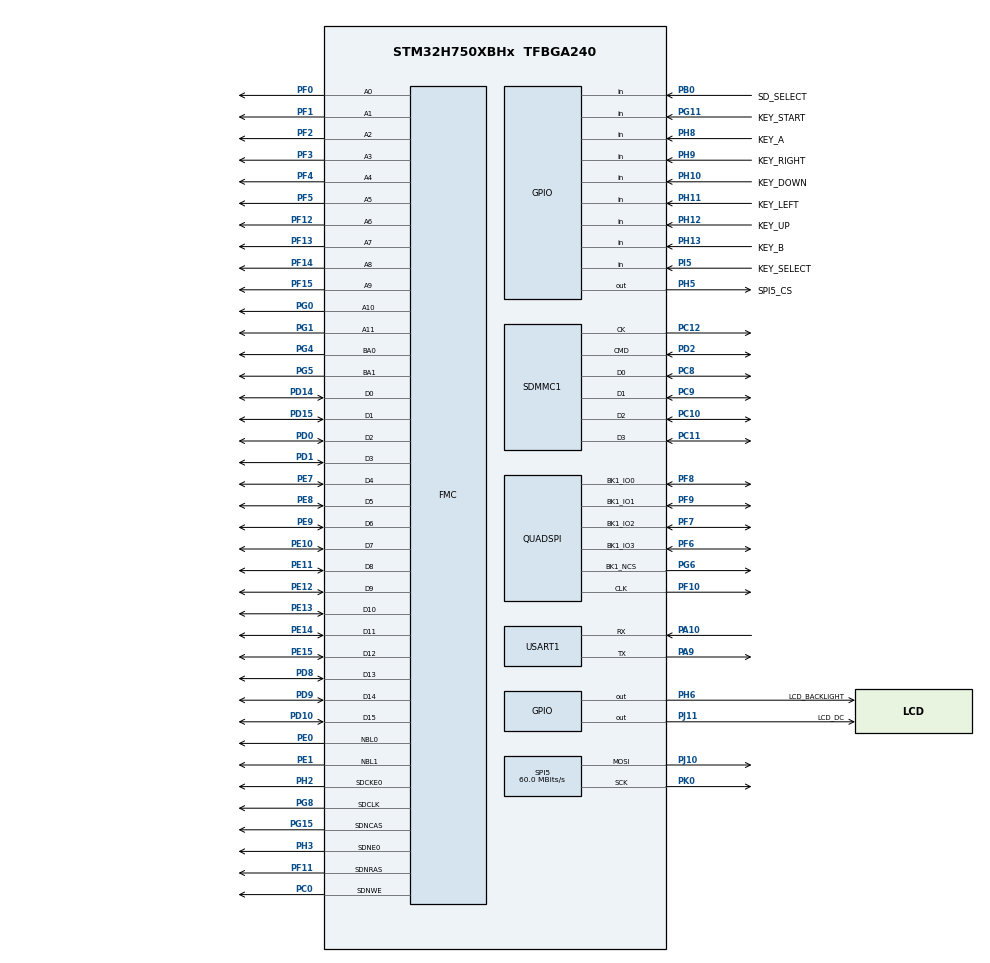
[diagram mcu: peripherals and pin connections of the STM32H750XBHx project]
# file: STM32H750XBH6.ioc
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CORTEX_M7.AccessPermission-Cortex_Memory_Protection_Unit_Region0_Settings=MPU_REGION_FULL_ACCESS
CORTEX_M7.AccessPermission-Cortex_Memory_Protection_Unit_Region1_Settings=MPU_REGION_FULL_ACCESS
CORTEX_M7.AccessPermission-Cortex_Memory_Protection_Unit_Region2_Settings=MPU_REGION_FULL_ACCESS
CORTEX_M7.BaseAddress-Cortex_Memory_Protection_Unit_Region0_Settings=0xC0000000
CORTEX_M7.BaseAddress-Cortex_Memory_Protection_Unit_Region1_Settings=0x38000000
CORTEX_M7.BaseAddress-Cortex_Memory_Protection_Unit_Region2_Settings=0x2407C000
CORTEX_M7.CPU_DCache=Enabled
CORTEX_M7.CPU_ICache=Enabled
CORTEX_M7.Enable-Cortex_Memory_Protection_Unit_Region0_Settings=MPU_REGION_ENABLE
CORTEX_M7.Enable-Cortex_Memory_Protection_Unit_Region1_Settings=MPU_REGION_ENABLE
CORTEX_M7.Enable-Cortex_Memory_Protection_Unit_Region2_Settings=MPU_REGION_ENABLE
CORTEX_M7.IsCacheable-Cortex_Memory_Protection_Unit_Region0_Settings=MPU_ACCESS_CACHEABLE
CORTEX_M7.MPU_Control=MPU_PRIVILEGED_DEFAULT
CORTEX_M7.Size-Cortex_Memory_Protection_Unit_Region0_Settings=MPU_REGION_SIZE_32MB
CORTEX_M7.Size-Cortex_Memory_Protection_Unit_Region1_Settings=MPU_REGION_SIZE_64KB
CORTEX_M7.Size-Cortex_Memory_Protection_Unit_Region2_Settings=MPU_REGION_SIZE_16KB
Dma.Request0=SPI5_TX
Dma.SPI5_TX.0.Direction=DMA_MEMORY_TO_PERIPH
Dma.SPI5_TX.0.EventEnable=DISABLE
Dma.SPI5_TX.0.FIFOMode=DMA_FIFOMODE_ENABLE
Dma.SPI5_TX.0.FIFOThreshold=DMA_FIFO_THRESHOLD_FULL
Dma.SPI5_TX.0.Instance=DMA1_Stream0
Dma.SPI5_TX.0.MemBurst=DMA_MBURST_SINGLE
Dma.SPI5_TX.0.MemDataAlignment=DMA_MDATAALIGN_BYTE
Dma.SPI5_TX.0.MemInc=DMA_MINC_ENABLE
Dma.SPI5_TX.0.Mode=DMA_NORMAL
Dma.SPI5_TX.0.PeriphBurst=DMA_PBURST_SINGLE
Dma.SPI5_TX.0.PeriphDataAlignment=DMA_PDATAALIGN_BYTE
Dma.SPI5_TX.0.PeriphInc=DMA_PINC_DISABLE
Dma.SPI5_TX.0.Polarity=HAL_DMAMUX_REQ_GEN_RISING
Dma.SPI5_TX.0.Priority=DMA_PRIORITY_LOW
Dma.SPI5_TX.0.RequestNumber=1
Dma.SPI5_TX.0.SignalID=NONE
Dma.SPI5_TX.0.SyncEnable=DISABLE
Dma.SPI5_TX.0.SyncPolarity=HAL_DMAMUX_SYNC_NO_EVENT
Dma.SPI5_TX.0.SyncRequestNumber=1
Dma.SPI5_TX.0.SyncSignalID=NONE
FATFS.BSP.number=1
FATFS._USE_LFN=2
FATFS._USE_STRFUNC=0
FATFS0.BSP.STBoard=false
FATFS0.BSP.api=Unknown
FATFS0.BSP.instance=PB0
FATFS0.BSP.ip=GPIO
FATFS0.BSP.mode=Input
FATFS0.BSP.name=Detect_SDIO
FATFS0.BSP.solution=PB0
FMC.CASLatency1=FMC_SDRAM_CAS_LATENCY_3
FMC.ColumnBitsNumber1=FMC_SDRAM_COLUMN_BITS_NUM_9
FMC.ExitSelfRefreshDelay1=7
FMC.LoadToActiveDelay1=2
FMC.RCDDelay1=2
FMC.RPDelay1=2
FMC.ReadBurst1=FMC_SDRAM_RBURST_ENABLE
FMC.ReadPipeDelay1=FMC_SDRAM_RPIPE_DELAY_0
FMC.RowCycleDelay1=7
FMC.SDClockPeriod1=FMC_SDRAM_CLOCK_PERIOD_2
FMC.SelfRefreshTime1=4
FMC.WriteRecoveryTime1=3
FREERTOS.Tasks01=defaultTask,8,128,StartDefaultTask,Default,NULL,Dynamic,NULL,NULL;displayTask,32,512,StartDisplayTask,Default,NULL,Dynamic,NULL,NULL;emuTask,24,512,StartEmuTask,Default,NULL,Dynamic,NULL,NULL
FREERTOS.configTIMER_TASK_PRIORITY=48
Mcu.Family=STM32H7
Mcu.Name=STM32H750XBHx
Mcu.Package=TFBGA240
Mdma.MDMA_Channel0.Request0=SDMMC1_END_DATA
Mdma.MDMA_Channel0.RequestsNb=1
Mdma.MDMA_Channel0.SDMMC1_END_DATA.0.BlockCount=0
Mdma.MDMA_Channel0.SDMMC1_END_DATA.0.BlockDataLength=0
Mdma.MDMA_Channel0.SDMMC1_END_DATA.0.BufferTransferLength=1
Mdma.MDMA_Channel0.SDMMC1_END_DATA.0.CircularMode=MDMA_LINEAR_LIST
Mdma.MDMA_Channel0.SDMMC1_END_DATA.0.DataAlignment=MDMA_DATAALIGN_PACKENABLE
Mdma.MDMA_Channel0.SDMMC1_END_DATA.0.DestBlockAddressOffset=0
Mdma.MDMA_Channel0.SDMMC1_END_DATA.0.DestBurst=MDMA_DEST_BURST_SINGLE
Mdma.MDMA_Channel0.SDMMC1_END_DATA.0.DestDataSize=MDMA_DEST_DATASIZE_BYTE
Mdma.MDMA_Channel0.SDMMC1_END_DATA.0.DestinationInc=MDMA_DEST_INC_BYTE
Mdma.MDMA_Channel0.SDMMC1_END_DATA.0.DstAddress=0
Mdma.MDMA_Channel0.SDMMC1_END_DATA.0.Endianness=MDMA_LITTLE_ENDIANNESS_PRESERVE
Mdma.MDMA_Channel0.SDMMC1_END_DATA.0.Instance=MDMA_Channel0
Mdma.MDMA_Channel0.SDMMC1_END_DATA.0.MaskAddress=0
Mdma.MDMA_Channel0.SDMMC1_END_DATA.0.MaskData=0
Mdma.MDMA_Channel0.SDMMC1_END_DATA.0.Priority=MDMA_PRIORITY_LOW
Mdma.MDMA_Channel0.SDMMC1_END_DATA.0.Rank=First
Mdma.MDMA_Channel0.SDMMC1_END_DATA.0.SourceBlockAddressOffset=0
Mdma.MDMA_Channel0.SDMMC1_END_DATA.0.SourceBurst=MDMA_SOURCE_BURST_SINGLE
Mdma.MDMA_Channel0.SDMMC1_END_DATA.0.SourceDataSize=MDMA_SRC_DATASIZE_BYTE
Mdma.MDMA_Channel0.SDMMC1_END_DATA.0.SourceInc=MDMA_SRC_INC_BYTE
Mdma.MDMA_Channel0.SDMMC1_END_DATA.0.SrcAddress=0
Mdma.MDMA_Channel0.SDMMC1_END_DATA.0.TransferTriggerMode=MDMA_BUFFER_TRANSFER
Mdma.RequestSet0=MDMA_Channel0
Mdma.RequestSetsNb=1
NVIC.DMA1_Stream0_IRQn=true\:5\:0\:false\:false\:true\:true\:false\:true\:true
NVIC.MDMA_IRQn=true\:5\:0\:false\:false\:true\:true\:false\:true\:true
NVIC.PriorityGroup=NVIC_PRIORITYGROUP_4
NVIC.SDMMC1_IRQn=true\:5\:0\:false\:false\:true\:true\:true\:true\:true
NVIC.SPI5_IRQn=true\:5\:0\:false\:false\:true\:true\:false\:true\:true
NVIC.TIM2_IRQn=true\:15\:0\:false\:false\:true\:false\:false\:true\:true
NVIC.TimeBase=TIM2_IRQn
NVIC.TimeBaseIP=TIM2
PA10.Mode=Asynchronous
PA10.Signal=USART1_RX
PA9.Mode=Asynchronous
PA9.Signal=USART1_TX
PB0.GPIO_Label=SD_SELECT
PB0.GPIO_PuPd=GPIO_PULLDOWN
PB0.Signal=GPIO_Input
PC0.Signal=FMC_SDNWE
PC10.Mode=SD_4_bits_Wide_bus
PC10.Signal=SDMMC1_D2
PC11.Mode=SD_4_bits_Wide_bus
PC11.Signal=SDMMC1_D3
PC12.Mode=SD_4_bits_Wide_bus
PC12.Signal=SDMMC1_CK
PC8.Mode=SD_4_bits_Wide_bus
PC8.Signal=SDMMC1_D0
PC9.Mode=SD_4_bits_Wide_bus
PC9.Signal=SDMMC1_D1
PD0.Signal=FMC_D2_DA2
PD1.Signal=FMC_D3_DA3
PD10.Signal=FMC_D15_DA15
PD14.Signal=FMC_D0_DA0
PD15.Signal=FMC_D1_DA1
PD2.Mode=SD_4_bits_Wide_bus
PD2.Signal=SDMMC1_CMD
PD8.Signal=FMC_D13_DA13
PD9.Signal=FMC_D14_DA14
PE0.Signal=FMC_NBL0
PE1.Signal=FMC_NBL1
PE10.Signal=FMC_D7_DA7
PE11.Signal=FMC_D8_DA8
PE12.Signal=FMC_D9_DA9
PE13.Signal=FMC_D10_DA10
PE14.Signal=FMC_D11_DA11
PE15.Signal=FMC_D12_DA12
PE7.Signal=FMC_D4_DA4
PE8.Signal=FMC_D5_DA5
PE9.Signal=FMC_D6_DA6
PF0.Signal=FMC_A0
PF1.Signal=FMC_A1
PF10.GPIO_Speed=GPIO_SPEED_FREQ_VERY_HIGH
PF10.Mode=Single Bank 1
PF10.Signal=QUADSPI_CLK
PF11.Signal=FMC_SDNRAS
PF12.Signal=FMC_A6
PF13.Signal=FMC_A7
PF14.Signal=FMC_A8
PF15.Signal=FMC_A9
PF2.Signal=FMC_A2
PF3.Signal=FMC_A3
PF4.Signal=FMC_A4
PF5.Signal=FMC_A5
PF6.GPIO_Speed=GPIO_SPEED_FREQ_VERY_HIGH
PF6.Mode=Single Bank 1
PF6.Signal=QUADSPI_BK1_IO3
PF7.GPIO_Speed=GPIO_SPEED_FREQ_VERY_HIGH
PF7.Mode=Single Bank 1
PF7.Signal=QUADSPI_BK1_IO2
PF8.GPIO_Speed=GPIO_SPEED_FREQ_VERY_HIGH
PF8.Mode=Single Bank 1
PF8.Signal=QUADSPI_BK1_IO0
PF9.GPIO_Speed=GPIO_SPEED_FREQ_VERY_HIGH
PF9.Mode=Single Bank 1
PF9.Signal=QUADSPI_BK1_IO1
PG0.Signal=FMC_A10
PG1.Signal=FMC_A11
PG11.GPIO_Label=KEY_START
PG11.GPIO_PuPd=GPIO_PULLUP
PG11.Signal=GPIO_Input
PG15.Signal=FMC_SDNCAS
PG4.Signal=FMC_A14_BA0
PG5.Signal=FMC_A15_BA1
PG6.GPIO_Speed=GPIO_SPEED_FREQ_VERY_HIGH
PG6.Mode=Single Bank 1
PG6.Signal=QUADSPI_BK1_NCS
PG8.Signal=FMC_SDCLK
PH0-OSC_IN\ (PH0).Mode=HSE-External-Oscillator
PH0-OSC_IN\ (PH0).Signal=RCC_OSC_IN
PH1-OSC_OUT\ (PH1).Mode=HSE-External-Oscillator
PH1-OSC_OUT\ (PH1).Signal=RCC_OSC_OUT
PH10.GPIO_Label=KEY_DOWN
PH10.GPIO_PuPd=GPIO_PULLUP
PH10.Signal=GPIO_Input
PH11.GPIO_Label=KEY_LEFT
PH11.GPIO_PuPd=GPIO_PULLUP
PH11.Signal=GPIO_Input
PH12.GPIO_Label=KEY_UP
PH12.GPIO_PuPd=GPIO_PULLUP
PH12.Signal=GPIO_Input
PH13.GPIO_Label=KEY_B
PH13.GPIO_PuPd=GPIO_PULLUP
PH13.Signal=GPIO_Input
PH2.Mode=SdramChipSelect1_1
PH2.Signal=FMC_SDCKE0
PH3.Mode=SdramChipSelect1_1
PH3.Signal=FMC_SDNE0
PH5.GPIO_Label=SPI5_CS
PH5.GPIO_Speed=GPIO_SPEED_FREQ_VERY_HIGH
PH5.Signal=GPIO_Output
PH6.GPIO_Label=LCD_BACKLIGHT
PH6.PinState=GPIO_PIN_SET
PH6.Signal=GPIO_Output
PH8.GPIO_Label=KEY_A
PH8.GPIO_PuPd=GPIO_PULLUP
PH8.Signal=GPIO_Input
PH9.GPIO_Label=KEY_RIGHT
PH9.GPIO_PuPd=GPIO_PULLUP
PH9.Signal=GPIO_Input
PI5.GPIO_Label=KEY_SELECT
PI5.GPIO_PuPd=GPIO_PULLUP
PI5.Signal=GPIO_Input
PJ10.GPIO_Speed=GPIO_SPEED_FREQ_VERY_HIGH
PJ10.Mode=TX_Only_Simplex_Unidirect_Master
PJ10.Signal=SPI5_MOSI
PJ11.GPIO_Label=LCD_DC
PJ11.PinState=GPIO_PIN_RESET
PJ11.Signal=GPIO_Output
PK0.GPIO_Speed=GPIO_SPEED_FREQ_VERY_HIGH
PK0.Mode=TX_Only_Simplex_Unidirect_Master
PK0.Signal=SPI5_SCK
ProjectManager.HeapSize=0x3000
ProjectManager.StackSize=0x2000
ProjectManager.TargetToolchain=MDK-ARM V5.32
QUADSPI.ClockMode=QSPI_CLOCK_MODE_0
QUADSPI.ClockPrescaler=1
QUADSPI.FifoThreshold=32
QUADSPI.FlashSize=23
QUADSPI.SampleShifting=QSPI_SAMPLE_SHIFTING_HALFCYCLE
RCC.ADCFreq_Value=50390625
RCC.APB1Freq_Value=120000000
RCC.APB2Freq_Value=120000000
RCC.APB3Freq_Value=120000000
RCC.APB4Freq_Value=120000000
RCC.CortexFreq_Value=480000000
RCC.D1PPRE=RCC_APB3_DIV2
RCC.D2PPRE1=RCC_APB1_DIV2
RCC.D2PPRE2=RCC_APB2_DIV2
RCC.D3PPRE=RCC_APB4_DIV2
RCC.DIVM1=5
RCC.DIVM3=5
RCC.DIVN1=192
RCC.DIVN3=100
RCC.DIVQ1=4
RCC.DIVQ3=50
RCC.DIVR3=50
RCC.HCLKFreq_Value=240000000
RCC.HPRE=RCC_HCLK_DIV2
RCC.PLLSourceVirtual=RCC_PLLSOURCE_HSE
RCC.ProductRev=revV
RCC.RTCClockSelection=RCC_RTCCLKSOURCE_LSE
RCC.SYSCLKFreq_VALUE=480000000
RCC.SYSCLKSource=RCC_SYSCLKSOURCE_PLLCLK
RCC.USBFreq_Value=240000000
SDMMC1.ClockDiv=2
SH.FMC_A0.0=FMC_A0,12b-sda1
SH.FMC_A1.0=FMC_A1,12b-sda1
SH.FMC_A10.0=FMC_A10,12b-sda1
SH.FMC_A11.0=FMC_A11,12b-sda1
SH.FMC_A14_BA0.0=FMC_BA0,FourSdramBanks1
SH.FMC_A15_BA1.0=FMC_BA1,FourSdramBanks1
SH.FMC_A2.0=FMC_A2,12b-sda1
SH.FMC_A3.0=FMC_A3,12b-sda1
SH.FMC_A4.0=FMC_A4,12b-sda1
SH.FMC_A5.0=FMC_A5,12b-sda1
SH.FMC_A6.0=FMC_A6,12b-sda1
SH.FMC_A7.0=FMC_A7,12b-sda1
SH.FMC_A8.0=FMC_A8,12b-sda1
SH.FMC_A9.0=FMC_A9,12b-sda1
SH.FMC_D0_DA0.0=FMC_D0,sd-16b-d1
SH.FMC_D10_DA10.0=FMC_D10,sd-16b-d1
SH.FMC_D11_DA11.0=FMC_D11,sd-16b-d1
SH.FMC_D12_DA12.0=FMC_D12,sd-16b-d1
SH.FMC_D13_DA13.0=FMC_D13,sd-16b-d1
SH.FMC_D14_DA14.0=FMC_D14,sd-16b-d1
SH.FMC_D15_DA15.0=FMC_D15,sd-16b-d1
SH.FMC_D1_DA1.0=FMC_D1,sd-16b-d1
SH.FMC_D2_DA2.0=FMC_D2,sd-16b-d1
SH.FMC_D3_DA3.0=FMC_D3,sd-16b-d1
SH.FMC_D4_DA4.0=FMC_D4,sd-16b-d1
SH.FMC_D5_DA5.0=FMC_D5,sd-16b-d1
SH.FMC_D6_DA6.0=FMC_D6,sd-16b-d1
SH.FMC_D7_DA7.0=FMC_D7,sd-16b-d1
SH.FMC_D8_DA8.0=FMC_D8,sd-16b-d1
SH.FMC_D9_DA9.0=FMC_D9,sd-16b-d1
SH.FMC_NBL0.0=FMC_NBL0,Sd2ByteEnable1
SH.FMC_NBL1.0=FMC_NBL1,Sd2ByteEnable1
SH.FMC_SDCLK.0=FMC_SDCLK,12b-sda1
SH.FMC_SDNCAS.0=FMC_SDNCAS,12b-sda1
SH.FMC_SDNRAS.0=FMC_SDNRAS,12b-sda1
SH.FMC_SDNWE.0=FMC_SDNWE,12b-sda1
SPI5.CalculateBaudRate=60.0 MBits/s
SPI5.DataSize=SPI_DATASIZE_8BIT
SPI5.Direction=SPI_DIRECTION_2LINES_TXONLY
SPI5.FifoThreshold=SPI_FIFO_THRESHOLD_02DATA
SPI5.Mode=SPI_MODE_MASTER
SPI5.VirtualType=VM_MASTER
STMicroelectronics.X-CUBE-TOUCHGFX.4.20.0.tgfx_address1=0xC0000000
STMicroelectronics.X-CUBE-TOUCHGFX.4.20.0.tgfx_address2=0xC00BB800
STMicroelectronics.X-CUBE-TOUCHGFX.4.20.0.tgfx_buffering_strategy=Double
STMicroelectronics.X-CUBE-TOUCHGFX.4.20.0.tgfx_custom_height=480
STMicroelectronics.X-CUBE-TOUCHGFX.4.20.0.tgfx_display_interface=disp_ltdc
STMicroelectronics.X-CUBE-TOUCHGFX.4.20.0.tgfx_hardware_accelerator=dma_2d
STMicroelectronics.X-CUBE-TOUCHGFX.4.20.0.tgfx_location=By Address
STMicroelectronics.X-CUBE-TOUCHGFX.4.20.0.tgfx_vsync=vsync_ltdc
STMicroelectronics.X-CUBE-TOUCHGFX.4.20.0_IsPackSelfContextualization=true
USART1.VirtualMode-Asynchronous=VM_ASYNC
VP_FATFS_VS_SDIO.Mode=SDIO
VP_FREERTOS_VS_CMSIS_V2.Mode=CMSIS_V2
VP_SYS_VS_tim2.Mode=TIM2
board=custom

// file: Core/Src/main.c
/* USER CODE BEGIN Header */
/**
  ******************************************************************************
  * @file           : main.c
  * @brief          : Main program body
  ******************************************************************************
  * @attention
  *
  * Copyright (c) 2023 STMicroelectronics.
  * All rights reserved.
  *
  * This software is licensed under terms that can be found in the LICENSE file
  * in the root directory of this software component.
  * If no LICENSE file comes with this software, it is provided AS-IS.
  *
  ******************************************************************************
  */
/* USER CODE END Header */
#include "main.h"
#include "cmsis_os.h"
#include "fatfs.h"

/* USER CODE BEGIN Includes */
#include <string.h>
#include "spi_drv.h"
#include "stm32h7_emu.h"
/* USER CODE END Includes */

QSPI_HandleTypeDef hqspi;

SD_HandleTypeDef hsd1;

SPI_HandleTypeDef hspi5;
DMA_HandleTypeDef hdma_spi5_tx;

UART_HandleTypeDef huart1;

MDMA_HandleTypeDef hmdma_mdma_channel0_sdmmc1_end_data_0;
SDRAM_HandleTypeDef hsdram1;

/* Definitions for defaultTask */
osThreadId_t defaultTaskHandle;
const osThreadAttr_t defaultTask_attributes = {
  .name = "defaultTask",
  .stack_size = 128 * 4,
  .priority = (osPriority_t) osPriorityLow,
};
/* Definitions for displayTask */
osThreadId_t displayTaskHandle;
const osThreadAttr_t displayTask_attributes = {
  .name = "displayTask",
  .stack_size = 512 * 4,
  .priority = (osPriority_t) osPriorityAboveNormal,
};
/* Definitions for emuTask */
osThreadId_t emuTaskHandle;
const osThreadAttr_t emuTask_attributes = {
  .name = "emuTask",
  .stack_size = 512 * 4,
  .priority = (osPriority_t) osPriorityNormal,
};

void SystemClock_Config(void);
static void MPU_Initialize(void);
static void MPU_Config(void);
static void MX_GPIO_Init(void);
static void MX_DMA_Init(void);
static void MX_MDMA_Init(void);
static void MX_QUADSPI_Init(void);
static void MX_SDMMC1_SD_Init(void);
static void MX_USART1_UART_Init(void);
static void MX_FMC_Init(void);
static void MX_SPI5_Init(void);
void StartDefaultTask(void *argument);
void StartDisplayTask(void *argument);
void StartEmuTask(void *argument);

/* USER CODE BEGIN 0 */
#define SDRAM_BANK_ADDR     ((uint32_t)0xC0000000) 				// FMC SDRAM 数据基地址
#define FMC_COMMAND_TARGET_BANK   FMC_SDRAM_CMD_TARGET_BANK1	//	SDRAM 的bank选择
#define SDRAM_TIMEOUT     ((uint32_t)0x1000) 						// 超时判断时间

#define SDRAM_MODEREG_BURST_LENGTH_1             ((uint16_t)0x0000)
#define SDRAM_MODEREG_BURST_LENGTH_2             ((uint16_t)0x0001)
#define SDRAM_MODEREG_BURST_LENGTH_4             ((uint16_t)0x0002)
#define SDRAM_MODEREG_BURST_LENGTH_8             ((uint16_t)0x0004)
#define SDRAM_MODEREG_BURST_TYPE_SEQUENTIAL      ((uint16_t)0x0000)
#define SDRAM_MODEREG_BURST_TYPE_INTERLEAVED     ((uint16_t)0x0008)
#define SDRAM_MODEREG_CAS_LATENCY_2              ((uint16_t)0x0020)
#define SDRAM_MODEREG_CAS_LATENCY_3              ((uint16_t)0x0030)
#define SDRAM_MODEREG_OPERATING_MODE_STANDARD    ((uint16_t)0x0000)
#define SDRAM_MODEREG_WRITEBURST_MODE_PROGRAMMED ((uint16_t)0x0000)
#define SDRAM_MODEREG_WRITEBURST_MODE_SINGLE     ((uint16_t)0x0200)

void SDRAM_Initialization_Sequence(SDRAM_HandleTypeDef *hsdram, FMC_SDRAM_CommandTypeDef *Command)
{
    __IO uint32_t tmpmrd = 0;

    /* Configure a clock configuration enable command */
    Command->CommandMode                = FMC_SDRAM_CMD_CLK_ENABLE;	// 开启SDRAM时钟
    Command->CommandTarget              = FMC_COMMAND_TARGET_BANK; 	// 选择要控制的区域
    Command->AutoRefreshNumber          = 1;
    Command->ModeRegisterDefinition     = 0;

    HAL_SDRAM_SendCommand(hsdram, Command, SDRAM_TIMEOUT);  // 发送控制指令
    HAL_Delay(1);		// 延时等待

    /* Configure a PALL (precharge all) command */
    Command->CommandMode                = FMC_SDRAM_CMD_PALL;       // 预充电命令
    Command->CommandTarget              = FMC_COMMAND_TARGET_BANK;  // 选择要控制的区域
    Command->AutoRefreshNumber          = 1;
    Command->ModeRegisterDefinition     = 0;

    HAL_SDRAM_SendCommand(hsdram, Command, SDRAM_TIMEOUT);  // 发送控制指令

    /* Configure a Auto-Refresh command */
    Command->CommandMode                = FMC_SDRAM_CMD_AUTOREFRESH_MODE;   // 使用自动刷新
    Command->CommandTarget              = FMC_COMMAND_TARGET_BANK;          // 选择要控制的区域
    Command->AutoRefreshNumber          = 8;                                // 自动刷新次数
    Command->ModeRegisterDefinition     = 0;

    HAL_SDRAM_SendCommand(hsdram, Command, SDRAM_TIMEOUT);  // 发送控制指令

    /* Program the external memory mode register */
    tmpmrd = (uint32_t)SDRAM_MODEREG_BURST_LENGTH_1 |
                            SDRAM_MODEREG_BURST_TYPE_SEQUENTIAL |
                            SDRAM_MODEREG_CAS_LATENCY_3 |
                            SDRAM_MODEREG_OPERATING_MODE_STANDARD   |
                            SDRAM_MODEREG_WRITEBURST_MODE_SINGLE;

    Command->CommandMode                = FMC_SDRAM_CMD_LOAD_MODE;  // 加载模式寄存器命令
    Command->CommandTarget              = FMC_COMMAND_TARGET_BANK;  // 选择要控制的区域
    Command->AutoRefreshNumber          = 1;
    Command->ModeRegisterDefinition     = tmpmrd;

    HAL_SDRAM_SendCommand(hsdram, Command, SDRAM_TIMEOUT);  // 发送控制指令

    HAL_SDRAM_ProgramRefreshRate(hsdram, 1543);  // 配置刷新率
}

/* USER CODE END 0 */

int main(void)
{

  /* Enable I-Cache---------------------------------------------------------*/
  SCB_EnableICache();

  /* Enable D-Cache---------------------------------------------------------*/
  SCB_EnableDCache();

  /* MCU Configuration--------------------------------------------------------*/

  /* Reset of all peripherals, Initializes the Flash interface and the Systick. */
  HAL_Init();

  /* MPU Configuration--------------------------------------------------------*/
  MPU_Config();

  /* Configure the system clock */
  SystemClock_Config();

  /* Initialize all configured peripherals */
  MX_GPIO_Init();
  MX_DMA_Init();
  MX_MDMA_Init();
  MX_QUADSPI_Init();
  MX_SDMMC1_SD_Init();
  MX_USART1_UART_Init();
  MX_FMC_Init();
  MX_SPI5_Init();
  MX_FATFS_Init();
  /* USER CODE BEGIN 2 */
  spi_init();
  /* USER CODE END 2 */

  /* Init scheduler */
  osKernelInitialize();

  /* Create the thread(s) */
  /* creation of defaultTask */
  defaultTaskHandle = osThreadNew(StartDefaultTask, NULL, &defaultTask_attributes);

  /* creation of displayTask */
  displayTaskHandle = osThreadNew(StartDisplayTask, NULL, &displayTask_attributes);

  /* creation of emuTask */
  emuTaskHandle = osThreadNew(StartEmuTask, NULL, &emuTask_attributes);

  /* Start scheduler */
  osKernelStart();

  /* We should never get here as control is now taken by the scheduler */
  /* Infinite loop */
  while (1)
  {

  }
}

void SystemClock_Config(void)
{
  RCC_OscInitTypeDef RCC_OscInitStruct = {0};
  RCC_ClkInitTypeDef RCC_ClkInitStruct = {0};

  /** Supply configuration update enable
  */
  HAL_PWREx_ConfigSupply(PWR_LDO_SUPPLY);

  /** Configure the main internal regulator output voltage
  */
  __HAL_PWR_VOLTAGESCALING_CONFIG(PWR_REGULATOR_VOLTAGE_SCALE1);

  while(!__HAL_PWR_GET_FLAG(PWR_FLAG_VOSRDY)) {}

  __HAL_RCC_SYSCFG_CLK_ENABLE();
  __HAL_PWR_VOLTAGESCALING_CONFIG(PWR_REGULATOR_VOLTAGE_SCALE0);

  while(!__HAL_PWR_GET_FLAG(PWR_FLAG_VOSRDY)) {}

  /** Initializes the RCC Oscillators according to the specified parameters
  * in the RCC_OscInitTypeDef structure.
  */
  RCC_OscInitStruct.OscillatorType = RCC_OSCILLATORTYPE_HSE;
  RCC_OscInitStruct.HSEState = RCC_HSE_ON;
  RCC_OscInitStruct.PLL.PLLState = RCC_PLL_ON;
  RCC_OscInitStruct.PLL.PLLSource = RCC_PLLSOURCE_HSE;
  RCC_OscInitStruct.PLL.PLLM = 5;
  RCC_OscInitStruct.PLL.PLLN = 192;
  RCC_OscInitStruct.PLL.PLLP = 2;
  RCC_OscInitStruct.PLL.PLLQ = 4;
  RCC_OscInitStruct.PLL.PLLR = 2;
  RCC_OscInitStruct.PLL.PLLRGE = RCC_PLL1VCIRANGE_2;
  RCC_OscInitStruct.PLL.PLLVCOSEL = RCC_PLL1VCOWIDE;
  RCC_OscInitStruct.PLL.PLLFRACN = 0;
  if (HAL_RCC_OscConfig(&RCC_OscInitStruct) != HAL_OK)
  {
    Error_Handler();
  }

  /** Initializes the CPU, AHB and APB buses clocks
  */
  RCC_ClkInitStruct.ClockType = RCC_CLOCKTYPE_HCLK|RCC_CLOCKTYPE_SYSCLK
                              |RCC_CLOCKTYPE_PCLK1|RCC_CLOCKTYPE_PCLK2
                              |RCC_CLOCKTYPE_D3PCLK1|RCC_CLOCKTYPE_D1PCLK1;
  RCC_ClkInitStruct.SYSCLKSource = RCC_SYSCLKSOURCE_PLLCLK;
  RCC_ClkInitStruct.SYSCLKDivider = RCC_SYSCLK_DIV1;
  RCC_ClkInitStruct.AHBCLKDivider = RCC_HCLK_DIV2;
  RCC_ClkInitStruct.APB3CLKDivider = RCC_APB3_DIV2;
  RCC_ClkInitStruct.APB1CLKDivider = RCC_APB1_DIV2;
  RCC_ClkInitStruct.APB2CLKDivider = RCC_APB2_DIV2;
  RCC_ClkInitStruct.APB4CLKDivider = RCC_APB4_DIV2;

  if (HAL_RCC_ClockConfig(&RCC_ClkInitStruct, FLASH_LATENCY_4) != HAL_OK)
  {
    Error_Handler();
  }
}

static void MX_QUADSPI_Init(void)
{

  /* QUADSPI parameter configuration*/
  hqspi.Instance = QUADSPI;
  hqspi.Init.ClockPrescaler = 1;
  hqspi.Init.FifoThreshold = 32;
  hqspi.Init.SampleShifting = QSPI_SAMPLE_SHIFTING_HALFCYCLE;
  hqspi.Init.FlashSize = 23;
  hqspi.Init.ChipSelectHighTime = QSPI_CS_HIGH_TIME_1_CYCLE;
  hqspi.Init.ClockMode = QSPI_CLOCK_MODE_0;
  hqspi.Init.FlashID = QSPI_FLASH_ID_1;
  hqspi.Init.DualFlash = QSPI_DUALFLASH_DISABLE;
  if (HAL_QSPI_Init(&hqspi) != HAL_OK)
  {
    Error_Handler();
  }

}

static void MX_SDMMC1_SD_Init(void)
{

  hsd1.Instance = SDMMC1;
  hsd1.Init.ClockEdge = SDMMC_CLOCK_EDGE_RISING;
  hsd1.Init.ClockPowerSave = SDMMC_CLOCK_POWER_SAVE_DISABLE;
  hsd1.Init.BusWide = SDMMC_BUS_WIDE_4B;
  hsd1.Init.HardwareFlowControl = SDMMC_HARDWARE_FLOW_CONTROL_DISABLE;
  hsd1.Init.ClockDiv = 2;

}

static void MX_SPI5_Init(void)
{

  /* SPI5 parameter configuration*/
  hspi5.Instance = SPI5;
  hspi5.Init.Mode = SPI_MODE_MASTER;
  hspi5.Init.Direction = SPI_DIRECTION_2LINES_TXONLY;
  hspi5.Init.DataSize = SPI_DATASIZE_8BIT;
  hspi5.Init.CLKPolarity = SPI_POLARITY_LOW;
  hspi5.Init.CLKPhase = SPI_PHASE_1EDGE;
  hspi5.Init.NSS = SPI_NSS_SOFT;
  hspi5.Init.BaudRatePrescaler = SPI_BAUDRATEPRESCALER_2;
  hspi5.Init.FirstBit = SPI_FIRSTBIT_MSB;
  hspi5.Init.TIMode = SPI_TIMODE_DISABLE;
  hspi5.Init.CRCCalculation = SPI_CRCCALCULATION_DISABLE;
  hspi5.Init.CRCPolynomial = 0x0;
  hspi5.Init.NSSPMode = SPI_NSS_PULSE_ENABLE;
  hspi5.Init.NSSPolarity = SPI_NSS_POLARITY_LOW;
  hspi5.Init.FifoThreshold = SPI_FIFO_THRESHOLD_02DATA;
  hspi5.Init.TxCRCInitializationPattern = SPI_CRC_INITIALIZATION_ALL_ZERO_PATTERN;
  hspi5.Init.RxCRCInitializationPattern = SPI_CRC_INITIALIZATION_ALL_ZERO_PATTERN;
  hspi5.Init.MasterSSIdleness = SPI_MASTER_SS_IDLENESS_00CYCLE;
  hspi5.Init.MasterInterDataIdleness = SPI_MASTER_INTERDATA_IDLENESS_00CYCLE;
  hspi5.Init.MasterReceiverAutoSusp = SPI_MASTER_RX_AUTOSUSP_DISABLE;
  hspi5.Init.MasterKeepIOState = SPI_MASTER_KEEP_IO_STATE_DISABLE;
  hspi5.Init.IOSwap = SPI_IO_SWAP_DISABLE;
  if (HAL_SPI_Init(&hspi5) != HAL_OK)
  {
    Error_Handler();
  }

}

static void MX_USART1_UART_Init(void)
{

  huart1.Instance = USART1;
  huart1.Init.BaudRate = 115200;
  huart1.Init.WordLength = UART_WORDLENGTH_8B;
  huart1.Init.StopBits = UART_STOPBITS_1;
  huart1.Init.Parity = UART_PARITY_NONE;
  huart1.Init.Mode = UART_MODE_TX_RX;
  huart1.Init.HwFlowCtl = UART_HWCONTROL_NONE;
  huart1.Init.OverSampling = UART_OVERSAMPLING_16;
  huart1.Init.OneBitSampling = UART_ONE_BIT_SAMPLE_DISABLE;
  huart1.Init.ClockPrescaler = UART_PRESCALER_DIV1;
  huart1.AdvancedInit.AdvFeatureInit = UART_ADVFEATURE_NO_INIT;
  if (HAL_UART_Init(&huart1) != HAL_OK)
  {
    Error_Handler();
  }
  if (HAL_UARTEx_SetTxFifoThreshold(&huart1, UART_TXFIFO_THRESHOLD_1_8) != HAL_OK)
  {
    Error_Handler();
  }
  if (HAL_UARTEx_SetRxFifoThreshold(&huart1, UART_RXFIFO_THRESHOLD_1_8) != HAL_OK)
  {
    Error_Handler();
  }
  if (HAL_UARTEx_DisableFifoMode(&huart1) != HAL_OK)
  {
    Error_Handler();
  }

}

static void MX_DMA_Init(void)
{

  /* DMA controller clock enable */
  __HAL_RCC_DMA1_CLK_ENABLE();

  /* DMA interrupt init */
  /* DMA1_Stream0_IRQn interrupt configuration */
  HAL_NVIC_SetPriority(DMA1_Stream0_IRQn, 5, 0);
  HAL_NVIC_EnableIRQ(DMA1_Stream0_IRQn);

}

/**
  * Enable MDMA controller clock
  * Configure MDMA for global transfers
  *   hmdma_mdma_channel0_sdmmc1_end_data_0
  */
static void MX_MDMA_Init(void)
{

  /* MDMA controller clock enable */
  __HAL_RCC_MDMA_CLK_ENABLE();
  /* Local variables */

  /* Configure MDMA channel MDMA_Channel0 */
  /* Configure MDMA request hmdma_mdma_channel0_sdmmc1_end_data_0 on MDMA_Channel0 */
  hmdma_mdma_channel0_sdmmc1_end_data_0.Instance = MDMA_Channel0;
  hmdma_mdma_channel0_sdmmc1_end_data_0.Init.Request = MDMA_REQUEST_SDMMC1_END_DATA;
  hmdma_mdma_channel0_sdmmc1_end_data_0.Init.TransferTriggerMode = MDMA_BUFFER_TRANSFER;
  hmdma_mdma_channel0_sdmmc1_end_data_0.Init.Priority = MDMA_PRIORITY_LOW;
  hmdma_mdma_channel0_sdmmc1_end_data_0.Init.Endianness = MDMA_LITTLE_ENDIANNESS_PRESERVE;
  hmdma_mdma_channel0_sdmmc1_end_data_0.Init.SourceInc = MDMA_SRC_INC_BYTE;
  hmdma_mdma_channel0_sdmmc1_end_data_0.Init.DestinationInc = MDMA_DEST_INC_BYTE;
  hmdma_mdma_channel0_sdmmc1_end_data_0.Init.SourceDataSize = MDMA_SRC_DATASIZE_BYTE;
  hmdma_mdma_channel0_sdmmc1_end_data_0.Init.DestDataSize = MDMA_DEST_DATASIZE_BYTE;
  hmdma_mdma_channel0_sdmmc1_end_data_0.Init.DataAlignment = MDMA_DATAALIGN_PACKENABLE;
  hmdma_mdma_channel0_sdmmc1_end_data_0.Init.BufferTransferLength = 1;
  hmdma_mdma_channel0_sdmmc1_end_data_0.Init.SourceBurst = MDMA_SOURCE_BURST_SINGLE;
  hmdma_mdma_channel0_sdmmc1_end_data_0.Init.DestBurst = MDMA_DEST_BURST_SINGLE;
  hmdma_mdma_channel0_sdmmc1_end_data_0.Init.SourceBlockAddressOffset = 0;
  hmdma_mdma_channel0_sdmmc1_end_data_0.Init.DestBlockAddressOffset = 0;
  if (HAL_MDMA_Init(&hmdma_mdma_channel0_sdmmc1_end_data_0) != HAL_OK)
  {
    Error_Handler();
  }

  /* Configure post request address and data masks */
  if (HAL_MDMA_ConfigPostRequestMask(&hmdma_mdma_channel0_sdmmc1_end_data_0, 0, 0) != HAL_OK)
  {
    Error_Handler();
  }

  /* MDMA interrupt initialization */
  /* MDMA_IRQn interrupt configuration */
  HAL_NVIC_SetPriority(MDMA_IRQn, 5, 0);
  HAL_NVIC_EnableIRQ(MDMA_IRQn);

}

/* FMC initialization function */
static void MX_FMC_Init(void)
{

  FMC_SDRAM_TimingTypeDef SdramTiming = {0};

  /** Perform the SDRAM1 memory initialization sequence
  */
  hsdram1.Instance = FMC_SDRAM_DEVICE;
  /* hsdram1.Init */
  hsdram1.Init.SDBank = FMC_SDRAM_BANK1;
  hsdram1.Init.ColumnBitsNumber = FMC_SDRAM_COLUMN_BITS_NUM_9;
  hsdram1.Init.RowBitsNumber = FMC_SDRAM_ROW_BITS_NUM_12;
  hsdram1.Init.MemoryDataWidth = FMC_SDRAM_MEM_BUS_WIDTH_16;
  hsdram1.Init.InternalBankNumber = FMC_SDRAM_INTERN_BANKS_NUM_4;
  hsdram1.Init.CASLatency = FMC_SDRAM_CAS_LATENCY_3;
  hsdram1.Init.WriteProtection = FMC_SDRAM_WRITE_PROTECTION_DISABLE;
  hsdram1.Init.SDClockPeriod = FMC_SDRAM_CLOCK_PERIOD_2;
  hsdram1.Init.ReadBurst = FMC_SDRAM_RBURST_ENABLE;
  hsdram1.Init.ReadPipeDelay = FMC_SDRAM_RPIPE_DELAY_0;
  /* SdramTiming */
  SdramTiming.LoadToActiveDelay = 2;
  SdramTiming.ExitSelfRefreshDelay = 7;
  SdramTiming.SelfRefreshTime = 4;
  SdramTiming.RowCycleDelay = 7;
  SdramTiming.WriteRecoveryTime = 3;
  SdramTiming.RPDelay = 2;
  SdramTiming.RCDDelay = 2;

  if (HAL_SDRAM_Init(&hsdram1, &SdramTiming) != HAL_OK)
  {
    Error_Handler( );
  }

  /* USER CODE BEGIN FMC_Init 2 */
  FMC_SDRAM_CommandTypeDef command; // 控制指令
  SDRAM_Initialization_Sequence(&hsdram1,&command); //配置SDRAM
  /* USER CODE END FMC_Init 2 */
}

static void MX_GPIO_Init(void)
{
  GPIO_InitTypeDef GPIO_InitStruct = {0};

  /* GPIO Ports Clock Enable */
  __HAL_RCC_GPIOI_CLK_ENABLE();
  __HAL_RCC_GPIOC_CLK_ENABLE();
  __HAL_RCC_GPIOE_CLK_ENABLE();
  __HAL_RCC_GPIOG_CLK_ENABLE();
  __HAL_RCC_GPIOD_CLK_ENABLE();
  __HAL_RCC_GPIOA_CLK_ENABLE();
  __HAL_RCC_GPIOH_CLK_ENABLE();
  __HAL_RCC_GPIOF_CLK_ENABLE();
  __HAL_RCC_GPIOK_CLK_ENABLE();
  __HAL_RCC_GPIOJ_CLK_ENABLE();
  __HAL_RCC_GPIOB_CLK_ENABLE();

  /*Configure GPIO pin Output Level */
  HAL_GPIO_WritePin(LCD_DC_GPIO_Port, LCD_DC_Pin, GPIO_PIN_RESET);

  /*Configure GPIO pin Output Level */
  HAL_GPIO_WritePin(SPI5_CS_GPIO_Port, SPI5_CS_Pin, GPIO_PIN_RESET);

  /*Configure GPIO pin Output Level */
  HAL_GPIO_WritePin(LCD_BACKLIGHT_GPIO_Port, LCD_BACKLIGHT_Pin, GPIO_PIN_SET);

  /*Configure GPIO pin : KEY_SELECT_Pin */
  GPIO_InitStruct.Pin = KEY_SELECT_Pin;
  GPIO_InitStruct.Mode = GPIO_MODE_INPUT;
  GPIO_InitStruct.Pull = GPIO_PULLUP;
  HAL_GPIO_Init(KEY_SELECT_GPIO_Port, &GPIO_InitStruct);

  /*Configure GPIO pin : KEY_START_Pin */
  GPIO_InitStruct.Pin = KEY_START_Pin;
  GPIO_InitStruct.Mode = GPIO_MODE_INPUT;
  GPIO_InitStruct.Pull = GPIO_PULLUP;
  HAL_GPIO_Init(KEY_START_GPIO_Port, &GPIO_InitStruct);

  /*Configure GPIO pins : KEY_B_Pin KEY_DOWN_Pin KEY_LEFT_Pin KEY_RIGHT_Pin
                           KEY_UP_Pin KEY_A_Pin */
  GPIO_InitStruct.Pin = KEY_B_Pin|KEY_DOWN_Pin|KEY_LEFT_Pin|KEY_RIGHT_Pin
                          |KEY_UP_Pin|KEY_A_Pin;
  GPIO_InitStruct.Mode = GPIO_MODE_INPUT;
  GPIO_InitStruct.Pull = GPIO_PULLUP;
  HAL_GPIO_Init(GPIOH, &GPIO_InitStruct);

  /*Configure GPIO pin : LCD_DC_Pin */
  GPIO_InitStruct.Pin = LCD_DC_Pin;
  GPIO_InitStruct.Mode = GPIO_MODE_OUTPUT_PP;
  GPIO_InitStruct.Pull = GPIO_NOPULL;
  GPIO_InitStruct.Speed = GPIO_SPEED_FREQ_LOW;
  HAL_GPIO_Init(LCD_DC_GPIO_Port, &GPIO_InitStruct);

  /*Configure GPIO pin : SPI5_CS_Pin */
  GPIO_InitStruct.Pin = SPI5_CS_Pin;
  GPIO_InitStruct.Mode = GPIO_MODE_OUTPUT_PP;
  GPIO_InitStruct.Pull = GPIO_NOPULL;
  GPIO_InitStruct.Speed = GPIO_SPEED_FREQ_VERY_HIGH;
  HAL_GPIO_Init(SPI5_CS_GPIO_Port, &GPIO_InitStruct);

  /*Configure GPIO pin : LCD_BACKLIGHT_Pin */
  GPIO_InitStruct.Pin = LCD_BACKLIGHT_Pin;
  GPIO_InitStruct.Mode = GPIO_MODE_OUTPUT_PP;
  GPIO_InitStruct.Pull = GPIO_NOPULL;
  GPIO_InitStruct.Speed = GPIO_SPEED_FREQ_LOW;
  HAL_GPIO_Init(LCD_BACKLIGHT_GPIO_Port, &GPIO_InitStruct);

  /*Configure GPIO pin : SD_SELECT_Pin */
  GPIO_InitStruct.Pin = SD_SELECT_Pin;
  GPIO_InitStruct.Mode = GPIO_MODE_INPUT;
  GPIO_InitStruct.Pull = GPIO_PULLDOWN;
  HAL_GPIO_Init(SD_SELECT_GPIO_Port, &GPIO_InitStruct);

}

void StartDefaultTask(void *argument)
{
  /* USER CODE BEGIN 5 */
  /* Infinite loop */
  for(;;)
  {
    osDelay(1000);
  }
  /* USER CODE END 5 */
}

void StartDisplayTask(void *argument)
{
  /* USER CODE BEGIN StartDisplayTask */
  stm32h7_draw_init();
  /* Infinite loop */
  for(;;)
  {
    stm32h7_draw_handle();
  }
  /* USER CODE END StartDisplayTask */
}

void StartEmuTask(void *argument)
{
  /* USER CODE BEGIN StartEmuTask */
  stm32h7_emu_init();
  /* Infinite loop */
  for(;;)
  {
    stm32h7_emu_handle();
  }
  /* USER CODE END StartEmuTask */
}

/* MPU Configuration */

void MPU_Config(void)
{
  MPU_Region_InitTypeDef MPU_InitStruct = {0};

  /* Disables the MPU */
  HAL_MPU_Disable();

  /** Initializes and configures the Region and the memory to be protected
  */
  MPU_InitStruct.Enable = MPU_REGION_ENABLE;
  MPU_InitStruct.Number = MPU_REGION_NUMBER0;
  MPU_InitStruct.BaseAddress = 0xC0000000;
  MPU_InitStruct.Size = MPU_REGION_SIZE_32MB;
  MPU_InitStruct.SubRegionDisable = 0x0;
  MPU_InitStruct.TypeExtField = MPU_TEX_LEVEL0;
  MPU_InitStruct.AccessPermission = MPU_REGION_FULL_ACCESS;
  MPU_InitStruct.DisableExec = MPU_INSTRUCTION_ACCESS_ENABLE;
  MPU_InitStruct.IsShareable = MPU_ACCESS_NOT_SHAREABLE;
  MPU_InitStruct.IsCacheable = MPU_ACCESS_CACHEABLE;
  MPU_InitStruct.IsBufferable = MPU_ACCESS_NOT_BUFFERABLE;

  HAL_MPU_ConfigRegion(&MPU_InitStruct);

  /** Initializes and configures the Region and the memory to be protected
  */
  MPU_InitStruct.Number = MPU_REGION_NUMBER1;
  MPU_InitStruct.BaseAddress = 0x38000000;
  MPU_InitStruct.Size = MPU_REGION_SIZE_64KB;
  MPU_InitStruct.IsCacheable = MPU_ACCESS_NOT_CACHEABLE;

  HAL_MPU_ConfigRegion(&MPU_InitStruct);

  /** Initializes and configures the Region and the memory to be protected
  */
  MPU_InitStruct.Number = MPU_REGION_NUMBER2;
  MPU_InitStruct.BaseAddress = 0x2407C000;
  MPU_InitStruct.Size = MPU_REGION_SIZE_16KB;

  HAL_MPU_ConfigRegion(&MPU_InitStruct);
  /* Enables the MPU */
  HAL_MPU_Enable(MPU_PRIVILEGED_DEFAULT);

}

void HAL_TIM_PeriodElapsedCallback(TIM_HandleTypeDef *htim)
{
  if (htim->Instance == TIM2) {
    HAL_IncTick();
  }
}

void Error_Handler(void)
{
  __disable_irq();
  while (1)
  {
  }
}
